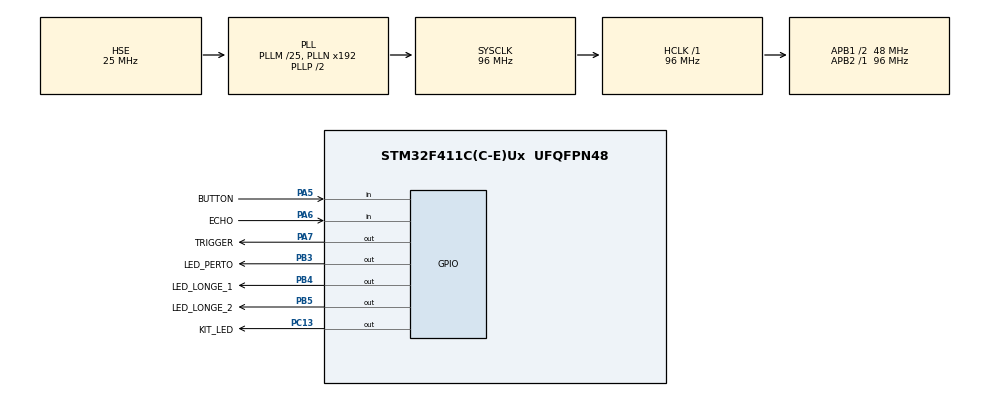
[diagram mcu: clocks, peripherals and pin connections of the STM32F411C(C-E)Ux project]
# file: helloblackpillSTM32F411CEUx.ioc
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Mcu.Family=STM32F4
Mcu.Name=STM32F411C(C-E)Ux
Mcu.Package=UFQFPN48
NVIC.PriorityGroup=NVIC_PRIORITYGROUP_4
PA13.Mode=Serial_Wire
PA13.Signal=SYS_JTMS-SWDIO
PA14.Mode=Serial_Wire
PA14.Signal=SYS_JTCK-SWCLK
PA5.GPIO_Label=BUTTON
PA5.Signal=GPIO_Input
PA6.GPIO_Label=ECHO
PA6.Signal=GPIO_Input
PA7.GPIO_Label=TRIGGER
PA7.Signal=GPIO_Output
PB3.GPIO_Label=LED_PERTO
PB3.Signal=GPIO_Output
PB4.GPIO_Label=LED_LONGE_1
PB4.Signal=GPIO_Output
PB5.GPIO_Label=LED_LONGE_2
PB5.Signal=GPIO_Output
PC13-ANTI_TAMP.GPIO_Label=KIT_LED
PC13-ANTI_TAMP.Signal=GPIO_Output
PC14-OSC32_IN.Mode=LSE-External-Oscillator
PC14-OSC32_IN.Signal=RCC_OSC32_IN
PC15-OSC32_OUT.Mode=LSE-External-Oscillator
PC15-OSC32_OUT.Signal=RCC_OSC32_OUT
PH0\ -\ OSC_IN.Mode=HSE-External-Oscillator
PH0\ -\ OSC_IN.Signal=RCC_OSC_IN
PH1\ -\ OSC_OUT.Mode=HSE-External-Oscillator
PH1\ -\ OSC_OUT.Signal=RCC_OSC_OUT
ProjectManager.HeapSize=0x200
ProjectManager.StackSize=0x400
ProjectManager.TargetToolchain=Makefile
RCC.48MHZClocksFreq_Value=48000000
RCC.AHBFreq_Value=96000000
RCC.APB1CLKDivider=RCC_HCLK_DIV2
RCC.APB1Freq_Value=48000000
RCC.APB1TimFreq_Value=96000000
RCC.APB2Freq_Value=96000000
RCC.APB2TimFreq_Value=96000000
RCC.CortexFreq_Value=96000000
RCC.HCLKFreq_Value=96000000
RCC.HSE_VALUE=25000000
RCC.HSI_VALUE=16000000
RCC.PLLM=25
RCC.PLLSourceVirtual=RCC_PLLSOURCE_HSE
RCC.SYSCLKFreq_VALUE=96000000
RCC.SYSCLKSource=RCC_SYSCLKSOURCE_PLLCLK
RCC.VCOOutputFreq_Value=192000000
board=custom

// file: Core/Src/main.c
/* USER CODE BEGIN Header */
/**
  ******************************************************************************
  * @file           : main.c
  * @brief          : Main program body
  ******************************************************************************
  * @attention
  *
  * Copyright (c) 2022 STMicroelectronics.
  * All rights reserved.
  *
  * This software is licensed under terms that can be found in the LICENSE file
  * in the root directory of this software component.
  * If no LICENSE file comes with this software, it is provided AS-IS.
  *
  ******************************************************************************
  */
/* USER CODE END Header */
#include "main.h"
#include "button.h"

void SystemClock_Config(void);
static void MX_GPIO_Init(void);

int main(void)
{
  /* USER CODE BEGIN 1 */
  uint32_t i;
  uint32_t lendo = 1;
  uint16_t existe_objeto = 0;
  uint16_t nao_existe_objeto = 0;
  /* USER CODE END 1 */

  /* MCU Configuration--------------------------------------------------------*/

  /* Reset of all peripherals, Initializes the Flash interface and the Systick. */
  HAL_Init();

  /* Configure the system clock */
  SystemClock_Config();

  /* Initialize all configured peripherals */
  MX_GPIO_Init();

  /* Infinite loop */
  /* USER CODE BEGIN WHILE */
  while (1)
  {

    if( button_release( GPIOA, GPIO_PIN_5, 0) )
    {

      HAL_GPIO_WritePin( GPIOA, TRIGGER_Pin, 1);
      HAL_Delay(10);
      HAL_GPIO_WritePin( GPIOA, TRIGGER_Pin, 0);

      while ( lendo == 1)
      {
        if( HAL_GPIO_ReadPin( GPIOA, ECHO_Pin ) == 1)
        {
          HAL_GPIO_WritePin( GPIOB, GPIO_PIN_4, 1 );
          HAL_GPIO_WritePin( GPIOB, GPIO_PIN_5, 1 );
          lendo = 0;
        }
        else
        {
          HAL_GPIO_WritePin( GPIOB, GPIO_PIN_3, 1 );

          if( button_release( GPIOA, GPIO_PIN_5, 0) )
          {
            lendo = 0;
            HAL_GPIO_WritePin( GPIOB, GPIO_PIN_3, 0 );
          }
        }
      }
      lendo = 1;

      HAL_GPIO_WritePin( GPIOB, GPIO_PIN_4, 0 );
      HAL_GPIO_WritePin( GPIOB, GPIO_PIN_5, 0 );

      HAL_Delay(1000);

    // if( button_release( GPIOA, GPIO_PIN_5, 0) )
    // {

    //   HAL_GPIO_WritePin( GPIOB, GPIO_PIN_4, 0 );
    //   HAL_GPIO_WritePin( GPIOB, GPIO_PIN_3, 0 );

    //   HAL_GPIO_WritePin( GPIOA, GPIO_PIN_7, 1);
    //   HAL_Delay(30);
    //   HAL_GPIO_WritePin( GPIOA, GPIO_PIN_7, 0);

    //   while ( lendo )
    //   {
    //     if( HAL_GPIO_ReadPin( GPIOA, GPIO_PIN_6 ) )
    //     {
    //       HAL_GPIO_WritePin( GPIOB, GPIO_PIN_4, 1 );
    //       HAL_GPIO_WritePin( GPIOB, GPIO_PIN_5, 1 );
    //       lendo--;
    //     }
    //     else
    //     {
    //       HAL_GPIO_WritePin( GPIOB, GPIO_PIN_3, 1 );

    //       if( button_release( GPIOA, GPIO_PIN_5, 0) )
    //       {
    //         lendo--;
    //       }
    //     }
    //   }
    //   lendo++;

    }

      // if( HAL_GPIO_ReadPin( GPIOA, GPIO_PIN_6) )
      // {
      //   HAL_GPIO_WritePin( GPIOB, LED_PERTO_Pin, 0);
      //   HAL_GPIO_WritePin( GPIOB, LED_LONGE_1_Pin, 1);
      //   HAL_GPIO_WritePin( GPIOB, LED_LONGE_2_Pin, 1);
      // } else {
      //   HAL_GPIO_WritePin( GPIOB, LED_PERTO_Pin, 1);
      //   HAL_GPIO_WritePin( GPIOB, LED_LONGE_1_Pin, 0);
      //   HAL_GPIO_WritePin( GPIOB, LED_LONGE_2_Pin, 0);
      // }

    // HAL_GPIO_WritePin( GPIOA, TRIGGER_Pin, 1);
    // HAL_Delay(120);
    // HAL_GPIO_WritePin( GPIOA, TRIGGER_Pin, 0);

    // if( HAL_GPIO_ReadPin( GPIOA, ECHO_Pin) )
    // {
    //   HAL_GPIO_WritePin( GPIOB, LED_PERTO_Pin, 1);
    // } else {
    //   HAL_GPIO_WritePin( GPIOB, LED_PERTO_Pin, 0);
    // }

    // if( button_release( GPIOA, GPIO_PIN_5, 0) )
    // {
    //   HAL_GPIO_TogglePin( GPIOA, TRIGGER_Pin);

    //   if( !HAL_GPIO_ReadPin( GPIOA, ECHO_Pin) )
    //   {
    //     HAL_GPIO_WritePin( GPIOB, LED_PERTO_Pin, 1);
    //   } else {
    //     HAL_GPIO_WritePin( GPIOB, LED_PERTO_Pin, 0);
    //   }
    // }

      // if( !HAL_GPIO_ReadPin( GPIOA, ECHO_Pin) )
      // {
      //   HAL_GPIO_WritePin( GPIOB, LED_LONGE_1_Pin, 0);
      //   HAL_GPIO_WritePin( GPIOB, LED_LONGE_2_Pin, 0);

      //   HAL_GPIO_WritePin( GPIOB, LED_PERTO_Pin, 1);

      //   nao_existe_objeto++;
      // }
      // else
      // {
      //   HAL_GPIO_WritePin( GPIOB, LED_PERTO_Pin, 0);

      //   HAL_GPIO_WritePin( GPIOB, LED_LONGE_1_Pin, 1);
      //   HAL_GPIO_WritePin( GPIOB, LED_LONGE_2_Pin, 1);

      //   existe_objeto++;
      // }

  }
  /* USER CODE END 3 */
}

void SystemClock_Config(void)
{
  RCC_OscInitTypeDef RCC_OscInitStruct = {0};
  RCC_ClkInitTypeDef RCC_ClkInitStruct = {0};

  /** Configure the main internal regulator output voltage
  */
  __HAL_RCC_PWR_CLK_ENABLE();
  __HAL_PWR_VOLTAGESCALING_CONFIG(PWR_REGULATOR_VOLTAGE_SCALE1);

  /** Initializes the RCC Oscillators according to the specified parameters
  * in the RCC_OscInitTypeDef structure.
  */
  RCC_OscInitStruct.OscillatorType = RCC_OSCILLATORTYPE_HSE;
  RCC_OscInitStruct.HSEState = RCC_HSE_ON;
  RCC_OscInitStruct.PLL.PLLState = RCC_PLL_ON;
  RCC_OscInitStruct.PLL.PLLSource = RCC_PLLSOURCE_HSE;
  RCC_OscInitStruct.PLL.PLLM = 25;
  RCC_OscInitStruct.PLL.PLLN = 192;
  RCC_OscInitStruct.PLL.PLLP = RCC_PLLP_DIV2;
  RCC_OscInitStruct.PLL.PLLQ = 4;
  if (HAL_RCC_OscConfig(&RCC_OscInitStruct) != HAL_OK)
  {
    Error_Handler();
  }

  /** Initializes the CPU, AHB and APB buses clocks
  */
  RCC_ClkInitStruct.ClockType = RCC_CLOCKTYPE_HCLK|RCC_CLOCKTYPE_SYSCLK
                              |RCC_CLOCKTYPE_PCLK1|RCC_CLOCKTYPE_PCLK2;
  RCC_ClkInitStruct.SYSCLKSource = RCC_SYSCLKSOURCE_PLLCLK;
  RCC_ClkInitStruct.AHBCLKDivider = RCC_SYSCLK_DIV1;
  RCC_ClkInitStruct.APB1CLKDivider = RCC_HCLK_DIV2;
  RCC_ClkInitStruct.APB2CLKDivider = RCC_HCLK_DIV1;

  if (HAL_RCC_ClockConfig(&RCC_ClkInitStruct, FLASH_LATENCY_3) != HAL_OK)
  {
    Error_Handler();
  }
}

static void MX_GPIO_Init(void)
{
  GPIO_InitTypeDef GPIO_InitStruct = {0};

  /* GPIO Ports Clock Enable */
  __HAL_RCC_GPIOC_CLK_ENABLE();
  __HAL_RCC_GPIOH_CLK_ENABLE();
  __HAL_RCC_GPIOA_CLK_ENABLE();
  __HAL_RCC_GPIOB_CLK_ENABLE();

  /*Configure GPIO pin Output Level */
  HAL_GPIO_WritePin(KIT_LED_GPIO_Port, KIT_LED_Pin, GPIO_PIN_RESET);

  /*Configure GPIO pin Output Level */
  HAL_GPIO_WritePin(TRIGGER_GPIO_Port, TRIGGER_Pin, GPIO_PIN_RESET);

  /*Configure GPIO pin Output Level */
  HAL_GPIO_WritePin(GPIOB, LED_PERTO_Pin|LED_LONGE_1_Pin|LED_LONGE_2_Pin, GPIO_PIN_RESET);

  /*Configure GPIO pin : KIT_LED_Pin */
  GPIO_InitStruct.Pin = KIT_LED_Pin;
  GPIO_InitStruct.Mode = GPIO_MODE_OUTPUT_PP;
  GPIO_InitStruct.Pull = GPIO_NOPULL;
  GPIO_InitStruct.Speed = GPIO_SPEED_FREQ_LOW;
  HAL_GPIO_Init(KIT_LED_GPIO_Port, &GPIO_InitStruct);

  /*Configure GPIO pins : BUTTON_Pin ECHO_Pin */
  GPIO_InitStruct.Pin = BUTTON_Pin|ECHO_Pin;
  GPIO_InitStruct.Mode = GPIO_MODE_INPUT;
  GPIO_InitStruct.Pull = GPIO_NOPULL;
  HAL_GPIO_Init(GPIOA, &GPIO_InitStruct);

  /*Configure GPIO pin : TRIGGER_Pin */
  GPIO_InitStruct.Pin = TRIGGER_Pin;
  GPIO_InitStruct.Mode = GPIO_MODE_OUTPUT_PP;
  GPIO_InitStruct.Pull = GPIO_NOPULL;
  GPIO_InitStruct.Speed = GPIO_SPEED_FREQ_LOW;
  HAL_GPIO_Init(TRIGGER_GPIO_Port, &GPIO_InitStruct);

  /*Configure GPIO pins : LED_PERTO_Pin LED_LONGE_1_Pin LED_LONGE_2_Pin */
  GPIO_InitStruct.Pin = LED_PERTO_Pin|LED_LONGE_1_Pin|LED_LONGE_2_Pin;
  GPIO_InitStruct.Mode = GPIO_MODE_OUTPUT_PP;
  GPIO_InitStruct.Pull = GPIO_NOPULL;
  GPIO_InitStruct.Speed = GPIO_SPEED_FREQ_LOW;
  HAL_GPIO_Init(GPIOB, &GPIO_InitStruct);

}

void Error_Handler(void)
{
  __disable_irq();
  while (1)
  {
  }
}
